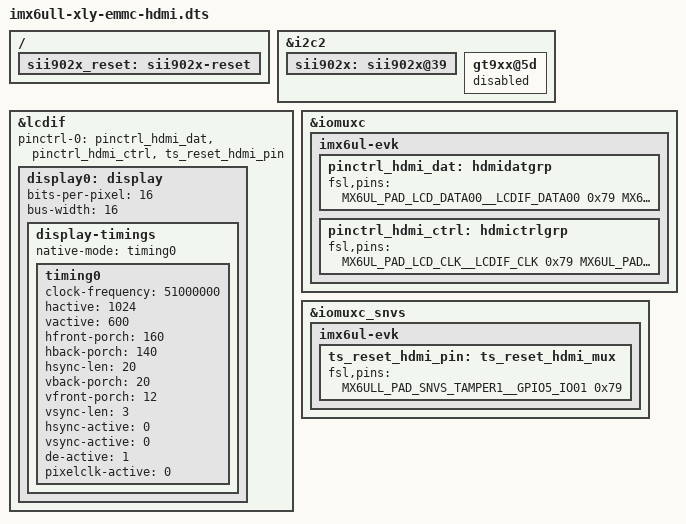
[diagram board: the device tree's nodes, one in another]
#include "imx6ull-14x14-evk-emmc.dts"

/ {
       sii902x_reset: sii902x-reset {
                status = "okay";
        };
};

&i2c2 {
	sii902x: sii902x@39{
		status = "okay";
	};

	gt9xx@5d {
		status = "disabled";
	};
};

&lcdif {
	pinctrl-0 = <&pinctrl_hdmi_dat
                        &pinctrl_hdmi_ctrl
                        &ts_reset_hdmi_pin>;

        display0: display {
		bits-per-pixel = <16>;
		bus-width = <16>;

		display-timings {
			native-mode = <&timing0>;
			timing0: timing0 {
			clock-frequency = <51000000>;
			hactive = <1024>;
			vactive = <600>;
			hfront-porch = <160>;
			hback-porch = <140>;
			hsync-len = <20>;
			vback-porch = <20>;
			vfront-porch = <12>;
			vsync-len = <3>;

			hsync-active = <0>;
			vsync-active = <0>;
			de-active = <1>;
			pixelclk-active = <0>;
			};
		};
	};
};

&iomuxc {
	imx6ul-evk {
                pinctrl_hdmi_dat: hdmidatgrp {
                        fsl,pins = <
                                MX6UL_PAD_LCD_DATA00__LCDIF_DATA00  0x79
                                MX6UL_PAD_LCD_DATA01__LCDIF_DATA01  0x79
                                MX6UL_PAD_LCD_DATA02__LCDIF_DATA02  0x79
                                MX6UL_PAD_LCD_DATA03__LCDIF_DATA03  0x79
                                MX6UL_PAD_LCD_DATA04__LCDIF_DATA04  0x79
                                MX6UL_PAD_LCD_DATA05__LCDIF_DATA05  0x79
                                MX6UL_PAD_LCD_DATA06__LCDIF_DATA06  0x79
                                MX6UL_PAD_LCD_DATA07__LCDIF_DATA07  0x79
                                MX6UL_PAD_LCD_DATA08__LCDIF_DATA08  0x79
                                MX6UL_PAD_LCD_DATA09__LCDIF_DATA09  0x79
                                MX6UL_PAD_LCD_DATA10__LCDIF_DATA10  0x79
                                MX6UL_PAD_LCD_DATA11__LCDIF_DATA11  0x79
                                MX6UL_PAD_LCD_DATA12__LCDIF_DATA12  0x79
                                MX6UL_PAD_LCD_DATA13__LCDIF_DATA13  0x79
                                MX6UL_PAD_LCD_DATA14__LCDIF_DATA14  0x79
                                MX6UL_PAD_LCD_DATA15__LCDIF_DATA15  0x79
                        >;
                };

                pinctrl_hdmi_ctrl: hdmictrlgrp {
                        fsl,pins = <
                                MX6UL_PAD_LCD_CLK__LCDIF_CLK        0x79
                                MX6UL_PAD_LCD_ENABLE__LCDIF_ENABLE  0x79
                                MX6UL_PAD_LCD_HSYNC__LCDIF_HSYNC    0x79
                                MX6UL_PAD_LCD_VSYNC__LCDIF_VSYNC    0x79
                        >;
                };

	};
};

&iomuxc_snvs {
	     imx6ul-evk {
                     ts_reset_hdmi_pin: ts_reset_hdmi_mux {
			fsl,pins = <
                                MX6ULL_PAD_SNVS_TAMPER1__GPIO5_IO01 0x79
                        >;
                };
	};
};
